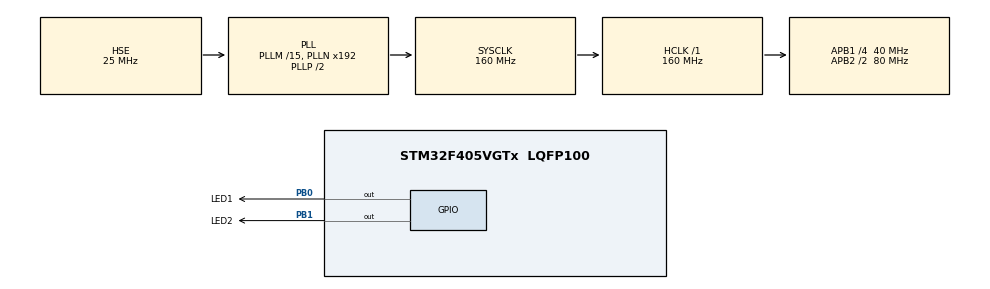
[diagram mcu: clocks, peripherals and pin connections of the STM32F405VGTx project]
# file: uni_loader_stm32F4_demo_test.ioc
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Mcu.Family=STM32F4
Mcu.Name=STM32F405VGTx
Mcu.Package=LQFP100
NVIC.PriorityGroup=NVIC_PRIORITYGROUP_4
NVIC.TIM6_DAC_IRQn=true\:0\:0\:false\:false\:true\:true\:true\:true
PA13.Mode=Serial_Wire
PA13.Signal=SYS_JTMS-SWDIO
PA14.Mode=Serial_Wire
PA14.Signal=SYS_JTCK-SWCLK
PB0.GPIO_Label=LED1
PB0.Signal=GPIO_Output
PB1.GPIO_Label=LED2
PB1.Signal=GPIO_Output
PC14-OSC32_IN.Mode=LSE-External-Oscillator
PC14-OSC32_IN.Signal=RCC_OSC32_IN
PC15-OSC32_OUT.Mode=LSE-External-Oscillator
PC15-OSC32_OUT.Signal=RCC_OSC32_OUT
PH0-OSC_IN.Mode=HSE-External-Oscillator
PH0-OSC_IN.Signal=RCC_OSC_IN
PH1-OSC_OUT.Mode=HSE-External-Oscillator
PH1-OSC_OUT.Signal=RCC_OSC_OUT
ProjectManager.HeapSize=0x200
ProjectManager.StackSize=0x400
ProjectManager.TargetToolchain=STM32CubeIDE
RCC.48MHZClocksFreq_Value=80000000
RCC.AHBFreq_Value=160000000
RCC.APB1CLKDivider=RCC_HCLK_DIV4
RCC.APB1Freq_Value=40000000
RCC.APB1TimFreq_Value=80000000
RCC.APB2CLKDivider=RCC_HCLK_DIV2
RCC.APB2Freq_Value=80000000
RCC.APB2TimFreq_Value=160000000
RCC.CortexFreq_Value=160000000
RCC.HCLKFreq_Value=160000000
RCC.HSE_VALUE=25000000
RCC.HSI_VALUE=16000000
RCC.PLLM=15
RCC.PLLSourceVirtual=RCC_PLLSOURCE_HSE
RCC.SYSCLKFreq_VALUE=160000000
RCC.SYSCLKSource=RCC_SYSCLKSOURCE_PLLCLK
RCC.VCOOutputFreq_Value=320000000
TIM6.Period=40000
TIM6.Prescaler=2
VP_TIM6_VS_ClockSourceINT.Mode=Enable_Timer
board=custom

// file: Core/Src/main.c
/* USER CODE BEGIN Header */
/**
  ******************************************************************************
  * @file           : main.c
  * @brief          : Main program body
  ******************************************************************************
  * @attention
  *
  * Copyright (c) 2022 STMicroelectronics.
  * All rights reserved.
  *
  * This software is licensed under terms that can be found in the LICENSE file
  * in the root directory of this software component.
  * If no LICENSE file comes with this software, it is provided AS-IS.
  *
  ******************************************************************************
  */
/* USER CODE END Header */
#include "main.h"

/* USER CODE BEGIN Includes */
#include <stdint.h>
#include <stdbool.h>

/* USER CODE END Includes */

TIM_HandleTypeDef htim6;

/* USER CODE BEGIN PV */
static bool App_1msElapsed;
static uint_fast16_t App_300msTimer;

/* USER CODE END PV */

void SystemClock_Config(void);
static void MX_GPIO_Init(void);
static void MX_TIM6_Init(void);

int main(void)
{

  /* MCU Configuration--------------------------------------------------------*/

  /* Reset of all peripherals, Initializes the Flash interface and the Systick. */
  HAL_Init();

  /* Configure the system clock */
  SystemClock_Config();

  /* Initialize all configured peripherals */
  MX_GPIO_Init();
  MX_TIM6_Init();
  /* USER CODE BEGIN 2 */
  App_1msElapsed = false;
  App_300msTimer = 0;

  HAL_TIM_PeriodElapsedCallback(&htim6);
  HAL_TIM_Base_Start_IT(&htim6);
  /* USER CODE END 2 */

  /* Infinite loop */
  while (1)
  {
	  if (true == App_1msElapsed)
	  {
		  App_1msElapsed = false;

		  if (++App_300msTimer >= 300)
		  {
			  App_300msTimer = 0;

			  HAL_GPIO_TogglePin(GPIOB, LED1_Pin | LED2_Pin);
		  }
	  }

  }
}

void SystemClock_Config(void)
{
  RCC_OscInitTypeDef RCC_OscInitStruct = {0};
  RCC_ClkInitTypeDef RCC_ClkInitStruct = {0};

  /** Configure the main internal regulator output voltage
  */
  __HAL_RCC_PWR_CLK_ENABLE();
  __HAL_PWR_VOLTAGESCALING_CONFIG(PWR_REGULATOR_VOLTAGE_SCALE1);

  /** Initializes the RCC Oscillators according to the specified parameters
  * in the RCC_OscInitTypeDef structure.
  */
  RCC_OscInitStruct.OscillatorType = RCC_OSCILLATORTYPE_HSE;
  RCC_OscInitStruct.HSEState = RCC_HSE_ON;
  RCC_OscInitStruct.PLL.PLLState = RCC_PLL_ON;
  RCC_OscInitStruct.PLL.PLLSource = RCC_PLLSOURCE_HSE;
  RCC_OscInitStruct.PLL.PLLM = 15;
  RCC_OscInitStruct.PLL.PLLN = 192;
  RCC_OscInitStruct.PLL.PLLP = RCC_PLLP_DIV2;
  RCC_OscInitStruct.PLL.PLLQ = 4;
  if (HAL_RCC_OscConfig(&RCC_OscInitStruct) != HAL_OK)
  {
    Error_Handler();
  }

  /** Initializes the CPU, AHB and APB buses clocks
  */
  RCC_ClkInitStruct.ClockType = RCC_CLOCKTYPE_HCLK|RCC_CLOCKTYPE_SYSCLK
                              |RCC_CLOCKTYPE_PCLK1|RCC_CLOCKTYPE_PCLK2;
  RCC_ClkInitStruct.SYSCLKSource = RCC_SYSCLKSOURCE_PLLCLK;
  RCC_ClkInitStruct.AHBCLKDivider = RCC_SYSCLK_DIV1;
  RCC_ClkInitStruct.APB1CLKDivider = RCC_HCLK_DIV4;
  RCC_ClkInitStruct.APB2CLKDivider = RCC_HCLK_DIV2;

  if (HAL_RCC_ClockConfig(&RCC_ClkInitStruct, FLASH_LATENCY_5) != HAL_OK)
  {
    Error_Handler();
  }
}

static void MX_TIM6_Init(void)
{

  TIM_MasterConfigTypeDef sMasterConfig = {0};

  htim6.Instance = TIM6;
  htim6.Init.Prescaler = 2;
  htim6.Init.CounterMode = TIM_COUNTERMODE_UP;
  htim6.Init.Period = 40000;
  htim6.Init.AutoReloadPreload = TIM_AUTORELOAD_PRELOAD_DISABLE;
  if (HAL_TIM_Base_Init(&htim6) != HAL_OK)
  {
    Error_Handler();
  }
  sMasterConfig.MasterOutputTrigger = TIM_TRGO_RESET;
  sMasterConfig.MasterSlaveMode = TIM_MASTERSLAVEMODE_DISABLE;
  if (HAL_TIMEx_MasterConfigSynchronization(&htim6, &sMasterConfig) != HAL_OK)
  {
    Error_Handler();
  }

}

static void MX_GPIO_Init(void)
{
  GPIO_InitTypeDef GPIO_InitStruct = {0};

  /* GPIO Ports Clock Enable */
  __HAL_RCC_GPIOC_CLK_ENABLE();
  __HAL_RCC_GPIOH_CLK_ENABLE();
  __HAL_RCC_GPIOB_CLK_ENABLE();
  __HAL_RCC_GPIOA_CLK_ENABLE();

  /*Configure GPIO pin Output Level */
  HAL_GPIO_WritePin(GPIOB, LED1_Pin|LED2_Pin, GPIO_PIN_RESET);

  /*Configure GPIO pins : LED1_Pin LED2_Pin */
  GPIO_InitStruct.Pin = LED1_Pin|LED2_Pin;
  GPIO_InitStruct.Mode = GPIO_MODE_OUTPUT_PP;
  GPIO_InitStruct.Pull = GPIO_NOPULL;
  GPIO_InitStruct.Speed = GPIO_SPEED_FREQ_LOW;
  HAL_GPIO_Init(GPIOB, &GPIO_InitStruct);

}

/* USER CODE BEGIN 4 */
void HAL_TIM_PeriodElapsedCallback(TIM_HandleTypeDef *htim)
{
	if (htim == &htim6)
	{
		App_1msElapsed = true;
	}
}

/* USER CODE END 4 */

void Error_Handler(void)
{
  __disable_irq();
  while (1)
  {
  }
}
